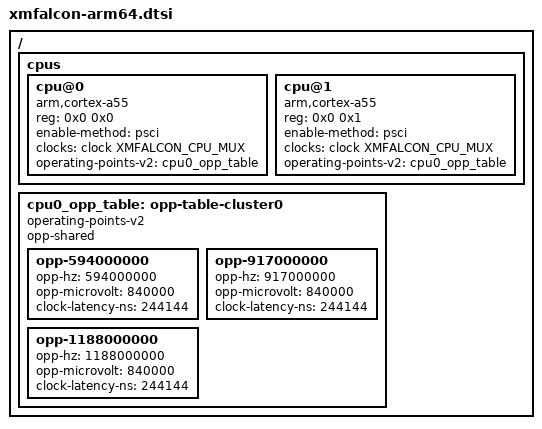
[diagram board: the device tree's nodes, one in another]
// SPDX-License-Identifier: GPL-2.0

/{
	cpus {
		#address-cells = <2>;
		#size-cells = <0>;

		cpu@0 {
			compatible = "arm,cortex-a55";
			device_type = "cpu";
			reg = <0x0 0x0>;
			enable-method = "psci";
			clocks = <&clock XMFALCON_CPU_MUX>;
			clock-names = "cpu";
			operating-points-v2 = <&cpu0_opp_table>;
		};

		cpu@1 {
			compatible = "arm,cortex-a55";
			device_type = "cpu";
			reg = <0x0 0x1>;
			enable-method = "psci";
			clocks = <&clock XMFALCON_CPU_MUX>;
			clock-names = "cpu";
			operating-points-v2 = <&cpu0_opp_table>;
		};
	};

	cpu0_opp_table: opp-table-cluster0 {
		compatible = "operating-points-v2";
		opp-shared;

		opp-594000000 {
			opp-hz = /bits/ 64 <594000000>;
			opp-microvolt = <840000>;
			clock-latency-ns = <244144>; /* 8 32k periods */
		};
		opp-917000000 {
			opp-hz = /bits/ 64 <917000000>;
			opp-microvolt = <840000>;
			clock-latency-ns = <244144>; /* 8 32k periods */
		};
		opp-1188000000 {
			opp-hz = /bits/ 64 <1188000000>;
			opp-microvolt = <840000>;
			clock-latency-ns = <244144>; /* 8 32k periods */
		};
	};

};
